# PIC32CM2532LE00064 register map
Vendor: Microchip Technology; Series: PIC32CMLE00; File version: 0
CPU: CM23 r0p0, little endian, MPU, no FPU, 2 interrupt priority bits, 71 interrupts
Registers are 32-bit, read-write, reset 0x0 unless marked. A register's access mark holds for its fields unless they carry their own. Offsets are from the block's base; [hi:lo] are bit positions; {n}, {i} and the like mark numbered series; 'fields as' and 'values as' point back to an identical list.

## DMAC — Direct Memory Access Controller
Base 0x41006000
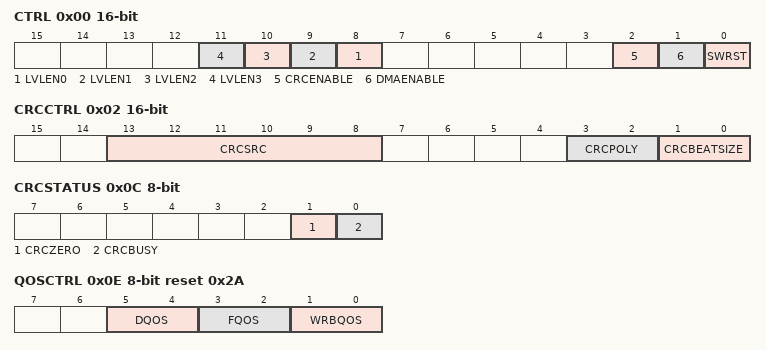
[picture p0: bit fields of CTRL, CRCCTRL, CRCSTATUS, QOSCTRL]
0x00 CTRL 16-bit — Control
  [n+8] LVLEN{n} (n=0..3) — Priority Level {n} Enable
  [2] CRCENABLE
  [1] DMAENABLE
  [0] SWRST — Software Reset
0x02 CRCCTRL 16-bit — CRC Control
  [13:8] CRCSRC — CRC Input Source
    0=NOACT (No action); 1=IO (I/O interface); {v}=CHN{v-32} (DMA Channel {v-32}) (v=32..47)
  [3:2] CRCPOLY — CRC Polynomial Type
    0=CRC16 (CRC-16 (CRC-CCITT)); 1=CRC32 (CRC32 (IEEE 802.3))
  [1:0] CRCBEATSIZE
    0=BYTE (8-bit bus transfer); 1=HWORD (16-bit bus transfer); 2=WORD (32-bit bus transfer)
0x04 CRCDATAIN — CRC Data Input
0x08 CRCCHKSUM — CRC Checksum
0x0C CRCSTATUS 8-bit
  [1] CRCZERO
  [0] CRCBUSY — CRC Module Busy
0x0D DBGCTRL 8-bit — Debug Control
  [0] DBGRUN — Debug Run
0x0E QOSCTRL 8-bit reset 0x2A — QOS Control
  [all] fields
    0=DISABLE (Background (no sensitive operation)); 1=LOW (Sensitive Bandwidth); 2=MEDIUM (Sensitive Latency); 3=HIGH (Critical Latency)
  [5:4] DQOS — Data Transfer Quality of Service
  [3:2] FQOS — Fetch Quality of Service
  [1:0] WRBQOS — Write-Back Quality of Service
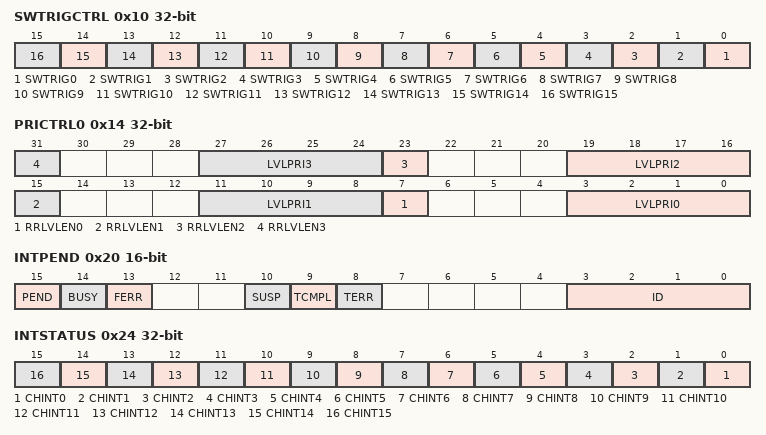
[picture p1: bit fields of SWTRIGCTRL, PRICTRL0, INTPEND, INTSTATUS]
0x10 SWTRIGCTRL — Software Trigger Control
  [n] SWTRIG{n} (n=0..15) — Channel {n} Software Trigger
0x14 PRICTRL0 — Priority Control
  [8n+7] RRLVLEN{n} (n=0..3) — Level {n} Round-Robin Scheduling Enable
    0=STATIC_LVL (Static arbitration scheme for channels with level {n} priority); 1=ROUND_ROBIN_LVL (Round-robin arbitration scheme for channels with level {n} priority)
  [8n+3:8n] LVLPRI{n} (n=0..3) — Level {n} Channel Priority Number
0x20 INTPEND 16-bit — Interrupt Pending
  [15] PEND — Pending
  [14] BUSY
  [13] FERR — Fetch Error
  [10] SUSP — Channel Suspend
  [9] TCMPL — Transfer Complete
  [8] TERR — Transfer Error
  [3:0] ID — Channel ID
0x24 INTSTATUS ro — Interrupt Status
  [n] CHINT{n} (n=0..15) — Channel {n} Pending Interrupt
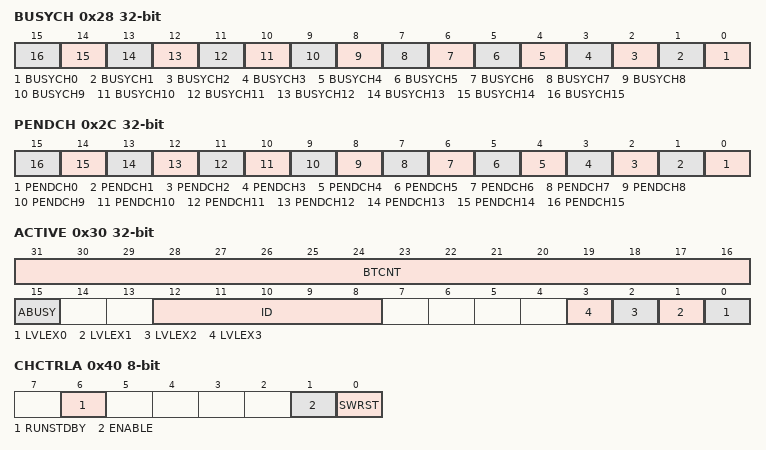
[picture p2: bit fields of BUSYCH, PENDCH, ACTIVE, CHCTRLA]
0x28 BUSYCH ro — Busy Channels
  [n] BUSYCH{n} (n=0..15) — Busy Channel {n}
0x2C PENDCH ro — Pending Channels
  [n] PENDCH{n} (n=0..15) — Pending Channel {n}
0x30 ACTIVE ro — Active Channel and Levels
  [31:16] BTCNT — Active Channel Block Transfer Count
  [15] ABUSY — Active Channel Busy
  [12:8] ID — Active Channel ID
  [n] LVLEX{n} (n=0..3) — Level {n} Channel Trigger Request Executing
0x34 BASEADDR — Descriptor Memory Section Base Address
  [31:0] BASEADDR — Descriptor Memory Base Address
0x38 WRBADDR — Write-Back Memory Section Base Address
  [31:0] WRBADDR — Write-Back Memory Base Address
0x3F CHID 8-bit — Channel ID
  [3:0] ID
0x40 CHCTRLA 8-bit — Channel Control A
  [6] RUNSTDBY — Channel run in standby
  [1] ENABLE — Channel Enable
  [0] SWRST — Channel Software Reset
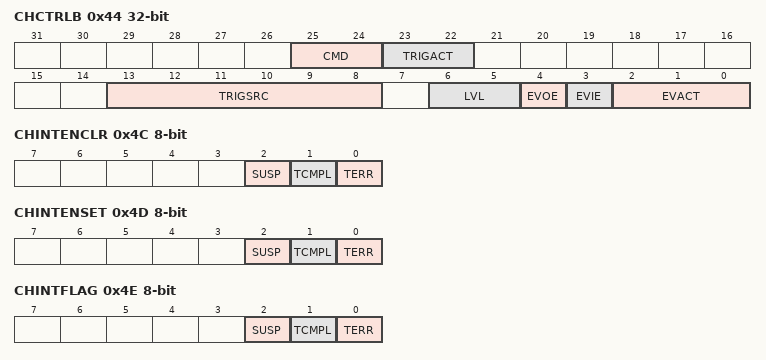
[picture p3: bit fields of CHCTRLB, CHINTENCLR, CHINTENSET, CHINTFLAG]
0x44 CHCTRLB — Channel Control B
  [25:24] CMD — Software Command
    0=NOACT (No action); 1=SUSPEND (Channel suspend operation); 2=RESUME (Channel resume operation)
  [23:22] TRIGACT — Trigger Action
    0=BLOCK (One trigger required for each block transfer); 2=BEAT (One trigger required for each beat transfer); 3=TRANSACTION (One trigger required for each transaction)
  [13:8] TRIGSRC — Trigger Source
    0=DISABLE (Only software/event triggers); 1=RTC_TIMESTAMP (RTC Timestamp Trigger); 2=DSU_DCC0 (ID for DCC0 register); 3=DSU_DCC1 (ID for DCC1 register); 4=SERCOM0_RX (SERCOM0 RX Trigger); 5=SERCOM0_TX (SERCOM0 TX Trigger); 6=SERCOM1_RX (SERCOM1 RX Trigger); 7=SERCOM1_TX (SERCOM1 TX Trigger); 8=SERCOM2_RX (SERCOM2 RX Trigger); 9=SERCOM2_TX (SERCOM2 TX Trigger); 10=SERCOM3_RX (SERCOM3 RX Trigger); 11=SERCOM3_TX (SERCOM3 TX Trigger); 12=SERCOM4_RX (SERCOM4 RX Trigger); 13=SERCOM4_TX (SERCOM4 TX Trigger); 14=SERCOM5_RX (SERCOM5 RX Trigger); 15=SERCOM5_TX (SERCOM5 TX Trigger); 16=TC0_OVF (TC0 Overflow Trigger); 17=TC0_MC0 (TC0 Match/Compare 0 Trigger); 18=TC0_MC1 (TC0 Match/Compare 1 Trigger); 19=TC1_OVF (TC1 Overflow Trigger); 20=TC1_MC0 (TC1 Match/Compare 0 Trigger); 21=TC1_MC1 (TC1 Match/Compare 1 Trigger); 22=TC2_OVF (TC2 Overflow Trigger); 23=TC2_MC0 (TC2 Match/Compare 0 Trigger); 24=TC2_MC1 (TC2 Match/Compare 1 Trigger); 25=TCC0_OVF (TCC0 Overflow Trigger); {v}=TCC0_MC{v-26} (TCC0 Match/Compare {v-26} Trigger) (v=26..29); 30=TCC1_OVF (TCC1 Overflow Trigger); 31=TCC1_MC0 (TCC1 Match/Compare 0 Trigger); 32=TCC1_MC1 (TCC1 Match/Compare 1 Trigger); 33=TCC2_OVF (TCC2 Overflow Trigger); 34=TCC2_MC0 (TCC2 Match/Compare 0 Trigger); 35=TCC2_MC1 (TCC2 Match/Compare 1 Trigger); 36=TCC3_OVF (TCC3 Overflow Trigger); {v}=TCC3_MC{v-37} (TCC3 Match/Compare {v-37} Trigger) (v=37..40); 41=ADC_RESRDY (ADC Result Ready Trigger); 42=DAC_EMPTY0 (DAC Empty 0 Trigger); 43=DAC_EMPTY1 (DAC Empty 1 Trigger); 44=PTC_EOC (PTC End of Conversion Trigger); 45=PTC_SEQ (PTC Sequence Trigger); 46=PTC_WCOMP (PTC Window Compare Trigger); 47=I2S_RX0 (I2S RX0 Trigger); 48=I2S_RX1 (I2S RX1 Trigger); 49=I2S_TX0 (I2S TX0 Trigger); 50=I2S_TX1 (I2S TX1 Trigger)
  [6:5] LVL — Channel Arbitration Level
    {v}=Channel Priority Level {v} (v=0..3)
  [4] EVOE — Channel Event Output Enable
  [3] EVIE — Channel Event Input Enable
  [2:0] EVACT — Event Input Action
    0=NOACT (No action); 1=TRIG (Transfer and periodic transfer trigger); 2=CTRIG (Conditional transfer trigger); 3=CBLOCK (Conditional block transfer); 4=SUSPEND (Channel suspend operation); 5=RESUME (Channel resume operation); 6=SSKIP (Skip next block suspend action)
0x4C CHINTENCLR 8-bit write-1-clears — Channel Interrupt Enable Clear
  [2] SUSP — Channel Suspend Interrupt Enable
  [1] TCMPL — Channel Transfer Complete Interrupt Enable
  [0] TERR — Channel Transfer Error Interrupt Enable
0x4D CHINTENSET 8-bit write-1-sets — Channel Interrupt Enable Set
  fields as CHINTENCLR
0x4E CHINTFLAG 8-bit write-1-clears — Channel Interrupt Flag Status and Clear
  [2] SUSP — Channel Suspend
  [1] TCMPL — Channel Transfer Complete
  [0] TERR — Channel Transfer Error
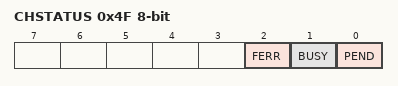
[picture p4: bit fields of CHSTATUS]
0x4F CHSTATUS 8-bit ro — Channel Status
  [2] FERR — Channel Fetch Error
  [1] BUSY — Channel Busy
  [0] PEND — Channel Pending

## Notices in the file
Copyright (c) 2026 Microchip Technology Inc.
SPDX-License-Identifier: Apache-2.0
Licensed under the Apache License, Version 2.0 (the "License");
you may not use this file except in compliance with the License.
You may obtain a copy of the License at
http://www.apache.org/licenses/LICENSE-2.0
Unless required by applicable law or agreed to in writing, software
distributed under the License is distributed on an "AS IS" BASIS,
WITHOUT WARRANTIES OR CONDITIONS OF ANY KIND, either express or implied.
See the License for the specific language governing permissions and
limitations under the License.
